# Musca_S1 register map
Vendor: ARM Ltd.; Series: ARMv8-M Mainline; File version: 1.0
CPU: CM33 r0p1, little endian, MPU, no FPU, 3 interrupt priority bits, 8 SAU regions
Registers are 32-bit, read-write, reset 0x0 unless marked. A register's access mark holds for its fields unless they carry their own. Offsets are from the block's base; [hi:lo] are bit positions; 'fields as' and 'values as' point back to an identical list.

## GPIO0 — General-purpose I/O 0
Base 0x40110000
Same registers: GPIO0_Secure 0x50110000
0x00 DATA
0x04 DATAOUT — Data Output Register
0x10 OUTENSET — Ouptut enable set Register
0x14 OUTENCLR — Ouptut enable clear Register
0x18 ALTFUNCSET — Alternate function set Register
0x1C ALTFUNCCLR — Alternate function clear Register
0x20 INTENSET — Interrupt enable set Register
0x24 INTENCLR — Interrupt enable clear Register
0x28 INTTYPESET — Interrupt type set Register
0x2C INTTYPECLR — Interrupt type clear Register
0x30 INTPOLSET — Polarity-level, edge interrupt configuration set Register
0x34 INTPOLCLR — Polarity-level, edge interrupt configuration clear Register
0x38 INTSTATUS ro — Interrupt Status Register
0x38 INTCLEAR wo write-1-clears (alternate view of INTSTATUS) — Interrupt CLEAR Register

## WATCHDOG — Non-secure Watchdog Timer
Base 0x40081000
Same registers: S32KWATCHDOG 0x4002E000, S32KWATCHDOG_Secure 0x5002E000, WATCHDOG_Secure 0x50081000
0x00 WDOGLOAD reset 0xFFFFFFFF — Watchdog Load Register
0x04 WDOGVALUE ro reset 0xFFFFFFFF — Watchdog Value Register
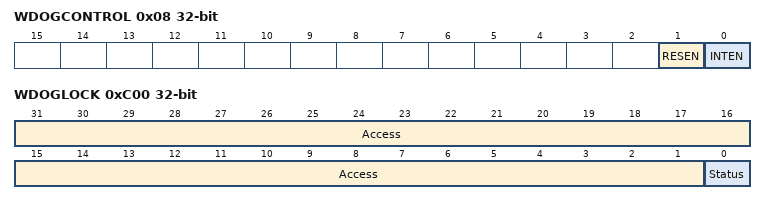
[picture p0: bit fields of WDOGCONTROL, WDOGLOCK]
0x08 WDOGCONTROL — Watchdog Control Register
  [1] RESEN — Enable watchdog reset output
    0=Disable Watchdog reset; 1=Enable Watchdog reset
  [0] INTEN — Enable the interrupt event
    0=Disable Watchdog Interrupt; 1=Enable Watchdog interrupt
0x0C WDOGINTCLR wo — Watchdog Interrupt Clear Register
  [0] INT write-1-clears — Interrupt
0x10 WDOGRIS ro — Watchdog Raw Interrupt Status Register
  [0] RIS — Raw watchdog Interrupt
0x14 WDOGMIS ro — Watchdog Mask Interrupt Status Register
  [0] MIS — Masked Watchdog Interrupt
0xC00 WDOGLOCK — Watchdog Lock Register
  [31:1] Access — Enable register writes
  [0] Status — Register write enable status
    0=Enabled (Write access to all other registers is enabled. This is the default); 1=Disabled (Write access to all other registers is disabled)

## I2C0
Base 0x40104000
Same registers: I2C1 0x40105000, I2C0_Secure 0x50104000, I2C1_Secure 0x50105000
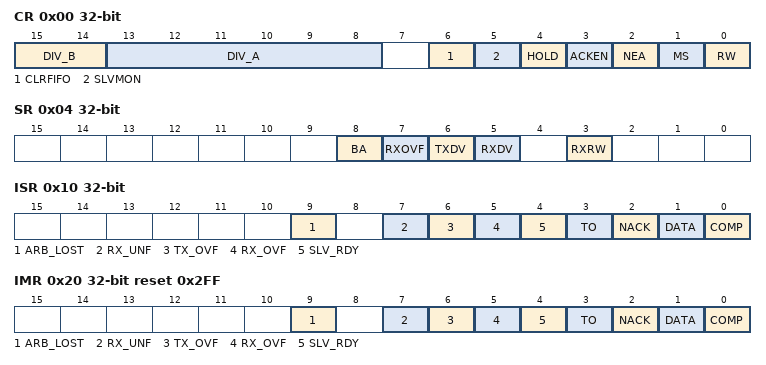
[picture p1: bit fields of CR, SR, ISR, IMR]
0x00 CR — Control Register
  [15:14] DIV_B — Divisor B: Divisor for stage B clock divider. Divides the output frequency from divisor_a by divisor_b + 1
  [13:8] DIV_A — Divisor A: Divisor for stage A clock divider. Divides the input pclk frequency by divisor_a + 1
  [6] CLRFIFO — Clear FIFO: initializes the FIFO to all zeros and clears the transfer size register
  [5] SLVMON — Slave Monitor mode: Slave monitor mode. 0 - normal operation, 1 - monitor mode
  [4] HOLD — Hold mode: Hold I2C sclk low until host services the data resources or clears this bit 1 - when no more data is available for transmit or no more data can be received, hold the sclk line low until serviced by the host. 0 - allow the transfer to terminate as soon as all the data has been transmitted or received. This bit has the same meaning in both master and slave modes.
  [3] ACKEN — Acknowledge Enable: Enable transmission of ACK when master-receiver 0 – acknowledge disabled, NACK transmitted, 1 – acknowledge enabled, ACK transmitted This bit must always be set if FIFO is implemented.
  [2] NEA — Normal/Extended Address:
  [1] MS — Master/Slave: Overall interface mode 0 - slave, 1 - master
  [0] RW — Read/Write: Direction of transfer 0 - master transmitter, 1 - master receiver This bit is used in master mode only.
0x04 SR ro — Status Register
  [8] BA — Bus Active: Indicates there is an ongoing transfer on the I2C bus. The I2C controller is not necessarily involved in it
  [7] RXOVF — Receiver Overflow: This flag is set when the receiver receives a byte of data before the previous byte has been read by the host.
  [6] TXDV — Transmitter Data Valid: Indicates that there is still a byte of data to be transmitted by the interface.
  [5] RXDV — Receiver Data Valid: Indicates that there is valid, new data to be read from the interface.
  [3] RXRW — RX read/write flag: Indicates the mode of the transmission received from a master.
0x08 AR — Address Register
  [9:0] ADD — I2C Address
0x0C DR — Data Register
  [7:0] DAT — I2C Data
0x10 ISR ro — Interrupt Status Register
  [9] ARB_LOST — Arbitration Lost
  [7] RX_UNF — FIFO Receive Underflow
  [6] TX_OVF — FIFO Transmit Overflow
  [5] RX_OVF — Receive Overflow
  [4] SLV_RDY — Monitored Slave Ready
  [3] TO — Transfer Time Out
  [2] NACK — Transfer Not Acknowledged
  [1] DATA — More Data
  [0] COMP — Transfer Complete
0x14 TSR — Transfer Size Register
  [3:0] TS — Transfer Size
0x18 SMPR — Slave Monitor Pause Register
  [3:0] PI — Pause Interval
0x1C TOR reset 0x1F — Time Out Register
  [7:0] TO — Time Out
0x20 IMR ro reset 0x2FF — Interrupt Mask Register
  fields as ISR
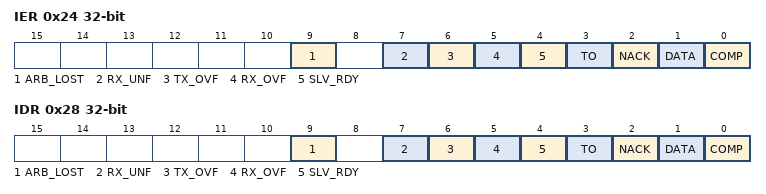
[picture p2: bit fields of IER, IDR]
0x24 IER wo — Interrupt Enable Register
  fields as ISR
0x28 IDR wo — Interrupt Disable Register
  fields as ISR
0x2C GFCR — Glitch Filter Control Register
  [3:0] GF — Glitch Filter depth
